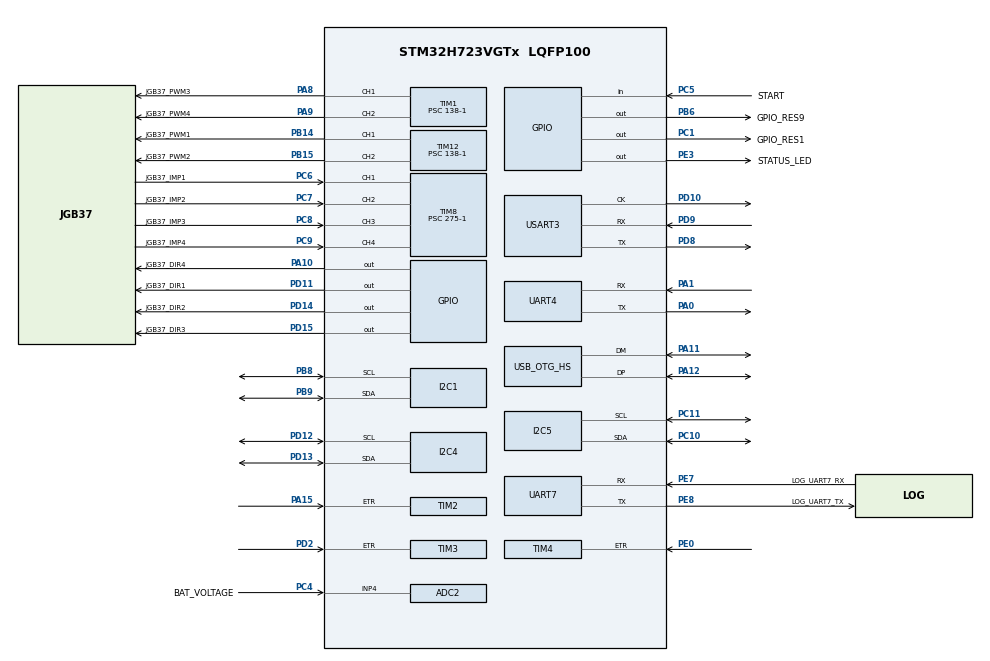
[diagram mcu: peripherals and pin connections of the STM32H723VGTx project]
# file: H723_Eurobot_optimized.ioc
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ADC2.Channel-0\#ChannelRegularConversion=ADC_CHANNEL_4
ADC2.NbrOfConversionFlag=1
ADC2.OffsetNumber-0\#ChannelRegularConversion=ADC_OFFSET_NONE
ADC2.OffsetSignedSaturation-0\#ChannelRegularConversion=DISABLE
ADC2.Rank-0\#ChannelRegularConversion=1
ADC2.SamplingTime-0\#ChannelRegularConversion=ADC_SAMPLETIME_1CYCLE_5
FREERTOS.Tasks01=defaultTask,24,3000,StartDefaultTask,Default,NULL,Dynamic,NULL,NULL;ServoTask,8,250,ServoSpinTask,Default,NULL,Dynamic,NULL,NULL
I2C1.Timing=0x60404E72
I2C4.Timing=0x60404E72
I2C5.Timing=0x60404E72
IWDG1.Prescaler=IWDG_PRESCALER_32
Mcu.Family=STM32H7
Mcu.Name=STM32H723VGTx
Mcu.Package=LQFP100
NVIC.OTG_HS_IRQn=true\:5\:0\:false\:false\:true\:true\:false\:true\:true
NVIC.PriorityGroup=NVIC_PRIORITYGROUP_4
NVIC.TIM5_IRQn=true\:15\:0\:false\:false\:true\:false\:false\:true\:true
NVIC.TIM8_CC_IRQn=true\:5\:0\:false\:false\:true\:true\:true\:true\:true
NVIC.TIM8_UP_TIM13_IRQn=true\:5\:0\:false\:false\:true\:true\:true\:true\:true
NVIC.TimeBase=TIM5_IRQn
NVIC.TimeBaseIP=TIM5
PA0.Mode=Asynchronous
PA0.Signal=UART4_TX
PA1.Mode=Asynchronous
PA1.Signal=UART4_RX
PA10.GPIO_Label=JGB37_DIR4
PA10.Signal=GPIO_Output
PA11.Mode=Device_Only_FS
PA11.Signal=USB_OTG_HS_DM
PA12.Mode=Device_Only_FS
PA12.Signal=USB_OTG_HS_DP
PA15(JTDI).Signal=S_TIM2_CH1_ETR
PA8.GPIO_Label=JGB37_PWM3
PA8.Signal=S_TIM1_CH1
PA9.GPIO_Label=JGB37_PWM4
PA9.Signal=S_TIM1_CH2
PB14.GPIO_Label=JGB37_PWM1
PB14.Signal=S_TIM12_CH1
PB15.GPIO_Label=JGB37_PWM2
PB15.Signal=S_TIM12_CH2
PB6.GPIO_Label=GPIO_RES9
PB6.Signal=GPIO_Output
PB8.Mode=I2C
PB8.Signal=I2C1_SCL
PB9.Mode=I2C
PB9.Signal=I2C1_SDA
PC1.GPIO_Label=GPIO_RES1
PC1.Signal=GPIO_Output
PC10.Mode=I2C
PC10.Signal=I2C5_SDA
PC11.Mode=I2C
PC11.Signal=I2C5_SCL
PC4.GPIO_Label=BAT_VOLTAGE
PC4.Signal=ADCx_INP4
PC5.GPIO_Label=START
PC5.Signal=GPIO_Input
PC6.GPIO_Label=JGB37_IMP1
PC6.Signal=S_TIM8_CH1
PC7.GPIO_Label=JGB37_IMP2
PC7.Signal=S_TIM8_CH2
PC8.GPIO_Label=JGB37_IMP3
PC8.Signal=S_TIM8_CH3
PC9.GPIO_Label=JGB37_IMP4
PC9.Signal=S_TIM8_CH4
PD10.Mode=Synchronous
PD10.Signal=USART3_CK
PD11.GPIO_Label=JGB37_DIR1
PD11.Signal=GPIO_Output
PD12.Mode=I2C
PD12.Signal=I2C4_SCL
PD13.Mode=I2C
PD13.Signal=I2C4_SDA
PD14.GPIO_Label=JGB37_DIR2
PD14.Signal=GPIO_Output
PD15.GPIO_Label=JGB37_DIR3
PD15.Signal=GPIO_Output
PD2.Signal=S_TIM3_ETR
PD8.Mode=Synchronous
PD8.Signal=USART3_TX
PD9.Mode=Synchronous
PD9.Signal=USART3_RX
PE0.Signal=S_TIM4_ETR
PE3.GPIO_Label=STATUS_LED
PE3.Signal=GPIO_Output
PE7.GPIO_Label=LOG_UART7_RX
PE7.Mode=Asynchronous
PE7.Signal=UART7_RX
PE8.GPIO_Label=LOG_UART7_TX
PE8.Mode=Asynchronous
PE8.Signal=UART7_TX
PH0-OSC_IN.Mode=HSE-External-Oscillator
PH0-OSC_IN.Signal=RCC_OSC_IN
PH1-OSC_OUT.Mode=HSE-External-Oscillator
PH1-OSC_OUT.Signal=RCC_OSC_OUT
ProjectManager.HeapSize=0x200
ProjectManager.StackSize=0x400
ProjectManager.TargetToolchain=STM32CubeIDE
RCC.ADCFreq_Value=129000000
RCC.APB1Freq_Value=137500000
RCC.APB2Freq_Value=137500000
RCC.APB3Freq_Value=137500000
RCC.APB4Freq_Value=137500000
RCC.CortexFreq_Value=550000000
RCC.D1PPRE=RCC_APB3_DIV2
RCC.D2PPRE1=RCC_APB1_DIV2
RCC.D2PPRE2=RCC_APB2_DIV2
RCC.D3PPRE=RCC_APB4_DIV2
RCC.DIVM1=4
RCC.DIVN1=34
RCC.DIVP1=1
RCC.HCLKFreq_Value=275000000
RCC.HPRE=RCC_HCLK_DIV2
RCC.PLL2FRACN=0
RCC.PLL3FRACN=0
RCC.PLLFRACN=3072
RCC.SYSCLKFreq_VALUE=550000000
RCC.SYSCLKSource=RCC_SYSCLKSOURCE_PLLCLK
RCC.USBCLockSelection=RCC_USBCLKSOURCE_HSI48
RCC.USBFreq_Value=48000000
SH.ADCx_INP4.0=ADC2_INP4,IN4-Single-Ended
SH.S_TIM12_CH1.0=TIM12_CH1,PWM Generation1 CH1
SH.S_TIM12_CH2.0=TIM12_CH2,PWM Generation2 CH2
SH.S_TIM1_CH1.0=TIM1_CH1,PWM Generation1 CH1
SH.S_TIM1_CH2.0=TIM1_CH2,PWM Generation2 CH2
SH.S_TIM2_CH1_ETR.0=TIM2_ETR,ClockSourceETR_Mode2
SH.S_TIM3_ETR.0=TIM3_ETR,ClockSourceETR_Mode2
SH.S_TIM4_ETR.0=TIM4_ETR,ClockSourceETR_Mode2
SH.S_TIM8_CH1.0=TIM8_CH1,Input_Capture1_from_TI1
SH.S_TIM8_CH2.0=TIM8_CH2,Input_Capture2_from_TI2
SH.S_TIM8_CH3.0=TIM8_CH3,Input_Capture3_from_TI3
SH.S_TIM8_CH4.0=TIM8_CH4,Input_Capture4_from_TI4
TIM1.Channel-PWM\ Generation1\ CH1=TIM_CHANNEL_1
TIM1.Channel-PWM\ Generation2\ CH2=TIM_CHANNEL_2
TIM1.Period=100
TIM1.Prescaler=138-1
TIM12.Channel-PWM\ Generation1\ CH1=TIM_CHANNEL_1
TIM12.Channel-PWM\ Generation2\ CH2=TIM_CHANNEL_2
TIM12.Period=100
TIM12.Prescaler=138-1
TIM23.Prescaler=275-1
TIM8.Channel-Input_Capture1_from_TI1=TIM_CHANNEL_1
TIM8.Channel-Input_Capture2_from_TI2=TIM_CHANNEL_2
TIM8.Channel-Input_Capture3_from_TI3=TIM_CHANNEL_3
TIM8.Channel-Input_Capture4_from_TI4=TIM_CHANNEL_4
TIM8.Prescaler=275-1
USART3.VirtualMode-Synchronous=VM_SYNC
USB_DEVICE.CLASS_NAME_HS=CDC
USB_DEVICE.VirtualMode=Cdc
USB_DEVICE.VirtualModeHS=Cdc_HS
USB_OTG_HS.VirtualMode-Device_Only_FS=Device_Only_FS
VP_FREERTOS_VS_CMSIS_V2.Mode=CMSIS_V2
VP_IWDG1_VS_IWDG.Mode=IWDG_Activate
VP_MEMORYMAP_VS_MEMORYMAP.Mode=CurAppReg
VP_SYS_VS_tim5.Mode=TIM5
VP_TIM12_VS_ClockSourceINT.Mode=Internal
VP_TIM1_VS_ClockSourceINT.Mode=Internal
VP_TIM23_VS_ClockSourceINT.Mode=Internal
VP_USB_DEVICE_VS_USB_DEVICE_CDC_HS.Mode=CDC_HS
board=custom

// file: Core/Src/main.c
/* USER CODE BEGIN Header */
/**
  ******************************************************************************
  * @file           : main.c
  * @brief          : Main program body
  ******************************************************************************
  * @attention
  *
  * Copyright (c) 2026 STMicroelectronics.
  * All rights reserved.
  *
  * This software is licensed under terms that can be found in the LICENSE file
  * in the root directory of this software component.
  * If no LICENSE file comes with this software, it is provided AS-IS.
  *
  ******************************************************************************
  */
/* USER CODE END Header */
#include "main.h"
#include "cmsis_os.h"
#include "adc.h"
#include "i2c.h"
#include "iwdg.h"
#include "tim.h"
#include "usart.h"
#include "usb_device.h"
#include "gpio.h"

void SystemClock_Config(void);
void MX_FREERTOS_Init(void);

int main(void)
{

  /* MCU Configuration--------------------------------------------------------*/

  /* Reset of all peripherals, Initializes the Flash interface and the Systick. */
  HAL_Init();

  /* Configure the system clock */
  SystemClock_Config();

  /* Initialize all configured peripherals */
  MX_GPIO_Init();
  MX_TIM8_Init();
  MX_UART4_Init();
  MX_IWDG1_Init();
  MX_ADC2_Init();
  MX_I2C4_Init();
  MX_TIM12_Init();
  MX_USART3_Init();
  MX_TIM2_Init();
  MX_TIM3_Init();
  MX_TIM4_Init();
  MX_TIM1_Init();
  MX_UART7_Init();
  MX_TIM23_Init();
  MX_I2C5_Init();
  MX_I2C1_Init();

  /* Init scheduler */
  osKernelInitialize();  /* Call init function for freertos objects (in cmsis_os2.c) */
  MX_FREERTOS_Init();

  /* Start scheduler */
  osKernelStart();

  /* We should never get here as control is now taken by the scheduler */

  /* Infinite loop */
  while (1)
  {

  }
}

void SystemClock_Config(void)
{
  RCC_OscInitTypeDef RCC_OscInitStruct = {0};
  RCC_ClkInitTypeDef RCC_ClkInitStruct = {0};

  /** Supply configuration update enable
  */
  HAL_PWREx_ConfigSupply(PWR_LDO_SUPPLY);

  /** Configure the main internal regulator output voltage
  */
  __HAL_PWR_VOLTAGESCALING_CONFIG(PWR_REGULATOR_VOLTAGE_SCALE0);

  while(!__HAL_PWR_GET_FLAG(PWR_FLAG_VOSRDY)) {}

  /** Initializes the RCC Oscillators according to the specified parameters
  * in the RCC_OscInitTypeDef structure.
  */
  RCC_OscInitStruct.OscillatorType = RCC_OSCILLATORTYPE_HSI48|RCC_OSCILLATORTYPE_HSI
                              |RCC_OSCILLATORTYPE_LSI;
  RCC_OscInitStruct.HSIState = RCC_HSI_DIV1;
  RCC_OscInitStruct.HSICalibrationValue = 64;
  RCC_OscInitStruct.LSIState = RCC_LSI_ON;
  RCC_OscInitStruct.HSI48State = RCC_HSI48_ON;
  RCC_OscInitStruct.PLL.PLLState = RCC_PLL_ON;
  RCC_OscInitStruct.PLL.PLLSource = RCC_PLLSOURCE_HSI;
  RCC_OscInitStruct.PLL.PLLM = 4;
  RCC_OscInitStruct.PLL.PLLN = 34;
  RCC_OscInitStruct.PLL.PLLP = 1;
  RCC_OscInitStruct.PLL.PLLQ = 2;
  RCC_OscInitStruct.PLL.PLLR = 2;
  RCC_OscInitStruct.PLL.PLLRGE = RCC_PLL1VCIRANGE_3;
  RCC_OscInitStruct.PLL.PLLVCOSEL = RCC_PLL1VCOWIDE;
  RCC_OscInitStruct.PLL.PLLFRACN = 3072;
  if (HAL_RCC_OscConfig(&RCC_OscInitStruct) != HAL_OK)
  {
    Error_Handler();
  }

  /** Initializes the CPU, AHB and APB buses clocks
  */
  RCC_ClkInitStruct.ClockType = RCC_CLOCKTYPE_HCLK|RCC_CLOCKTYPE_SYSCLK
                              |RCC_CLOCKTYPE_PCLK1|RCC_CLOCKTYPE_PCLK2
                              |RCC_CLOCKTYPE_D3PCLK1|RCC_CLOCKTYPE_D1PCLK1;
  RCC_ClkInitStruct.SYSCLKSource = RCC_SYSCLKSOURCE_PLLCLK;
  RCC_ClkInitStruct.SYSCLKDivider = RCC_SYSCLK_DIV1;
  RCC_ClkInitStruct.AHBCLKDivider = RCC_HCLK_DIV2;
  RCC_ClkInitStruct.APB3CLKDivider = RCC_APB3_DIV2;
  RCC_ClkInitStruct.APB1CLKDivider = RCC_APB1_DIV2;
  RCC_ClkInitStruct.APB2CLKDivider = RCC_APB2_DIV2;
  RCC_ClkInitStruct.APB4CLKDivider = RCC_APB4_DIV2;

  if (HAL_RCC_ClockConfig(&RCC_ClkInitStruct, FLASH_LATENCY_3) != HAL_OK)
  {
    Error_Handler();
  }
}

void HAL_TIM_PeriodElapsedCallback(TIM_HandleTypeDef *htim)
{
  if (htim->Instance == TIM5)
  {
    HAL_IncTick();
  }
}

void Error_Handler(void)
{
  __disable_irq();
  while (1)
  {
  }
}

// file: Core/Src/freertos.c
/* USER CODE BEGIN Header */
/**
  ******************************************************************************
  * File Name          : freertos.c
  * Description        : Code for freertos applications
  ******************************************************************************
  * @attention
  *
  * Copyright (c) 2026 STMicroelectronics.
  * All rights reserved.
  *
  * This software is licensed under terms that can be found in the LICENSE file
  * in the root directory of this software component.
  * If no LICENSE file comes with this software, it is provided AS-IS.
  *
  ******************************************************************************
  */

/* USER CODE END Header */

#include "FreeRTOS.h"
#include "task.h"
#include "main.h"
#include "cmsis_os.h"

/* USER CODE BEGIN Includes */
#include "MicroRos.h"
//#include "../../MicroRos/microros.h"  // если MicroRos выше
/* USER CODE END Includes */

/* Definitions for defaultTask */
osThreadId_t defaultTaskHandle;
const osThreadAttr_t defaultTask_attributes = {
  .name = "defaultTask",
  .stack_size = 3000 * 4,
  .priority = (osPriority_t) osPriorityNormal,
};
/* Definitions for ServoTask */
osThreadId_t ServoTaskHandle;
const osThreadAttr_t ServoTask_attributes = {
  .name = "ServoTask",
  .stack_size = 250 * 4,
  .priority = (osPriority_t) osPriorityLow,
};

void StartDefaultTask(void *argument);
void ServoSpinTask(void *argument);

extern void MX_USB_DEVICE_Init(void);
void MX_FREERTOS_Init(void); /* (MISRA C 2004 rule 8.1) */

void MX_FREERTOS_Init(void) {

  /* Create the thread(s) */
  /* creation of defaultTask */
  defaultTaskHandle = osThreadNew(StartDefaultTask, NULL, &defaultTask_attributes);

  /* creation of ServoTask */
  ServoTaskHandle = osThreadNew(ServoSpinTask, NULL, &ServoTask_attributes);

}

void StartDefaultTask(void *argument)
{
  /* init code for USB_DEVICE */
  MX_USB_DEVICE_Init();
  /* USER CODE BEGIN StartDefaultTask */
  MicroRosInit();
  /* Infinite loop */
  for(;;)
  {
//	  CDC_Transmit_HS("1234", 5);
	MicroRosExecute();
    osDelay(1);
  }
  /* USER CODE END StartDefaultTask */
}

void ServoSpinTask(void *argument)
{
  /* USER CODE BEGIN ServoSpinTask */
	ServoInit();
  /* Infinite loop */
  for(;;)
  {
	ServoSpin();
    osDelay(1);
  }
  /* USER CODE END ServoSpinTask */
}
